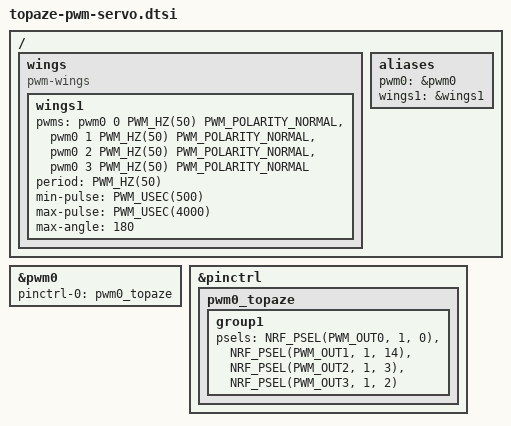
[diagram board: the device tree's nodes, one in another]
/* ============================================================
 * This file is the overlay DTS for topaze that define the PWM
 * peripheral for the servo engines specifically.
 *
 * We describe here the peripherals configuration, and so on...
 *
 * l.heywang
 * 01/03/2025
 *
 * ============================================================
 */

// ============================================================
// PWM
// ============================================================
// Peripheral configuration
&pwm0 {
    status = "okay";
    pinctrl-0 = <&pwm0_topaze>;
    pinctrl-names = "default";
};

// Pin muxing configuration
&pinctrl {
    pwm0_topaze: pwm0_topaze {
        group1 {
            psels =     <NRF_PSEL(PWM_OUT0, 1, 0)>,
                        <NRF_PSEL(PWM_OUT1, 1, 14)>, 
                        <NRF_PSEL(PWM_OUT2, 1, 3)>,
                        <NRF_PSEL(PWM_OUT3, 1, 2)>;
        };
    };
};

// Operating parameters configuration
/*
 * The pwms parameters are assigned in the following order : 
 *  - first :   north 
 *  - second :  south
 *  - third :   east
 *  - last :    west
 *
 * Direction are designated as :
 *
 *        North
 *          |
 *  West-- PCB -- East
 *          |
 *        South
 *
 */
/{
    wings {
        compatible = "pwm-wings";
        wings1: wings1 {
            pwms =      <&pwm0 0 PWM_HZ(50) PWM_POLARITY_NORMAL>, 
                        <&pwm0 1 PWM_HZ(50) PWM_POLARITY_NORMAL>,
                        <&pwm0 2 PWM_HZ(50) PWM_POLARITY_NORMAL>,
                        <&pwm0 3 PWM_HZ(50) PWM_POLARITY_NORMAL>;
            period =    <PWM_HZ(50)>;
            min-pulse = <PWM_USEC(500)>;
            max-pulse = <PWM_USEC(4000)>;
            max-angle = <180>;
        };
    };
};

// Set aliases for this module
/{
    aliases {
        pwm0    =  &pwm0;
        wings1  = &wings1;
    };
};








